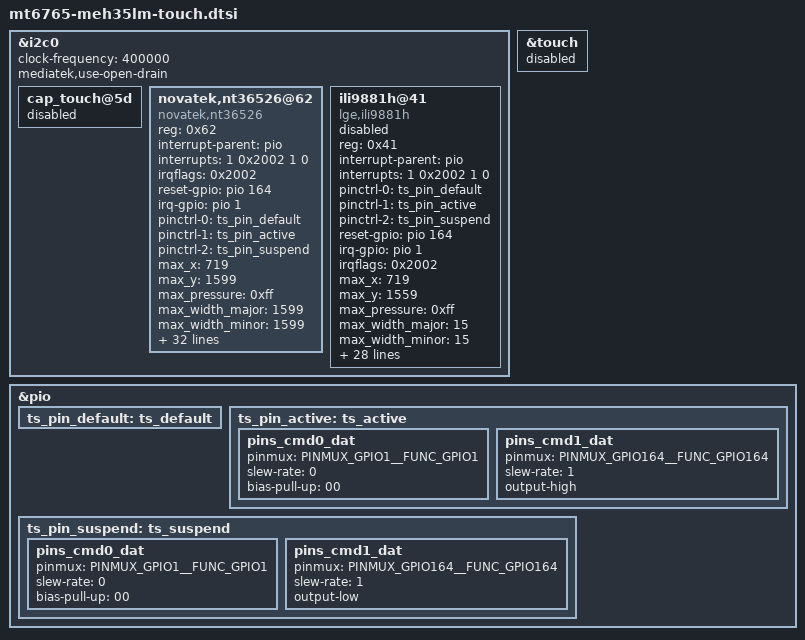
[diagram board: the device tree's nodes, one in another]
/*
 * Copyright (c) 2016, The Linux Foundation. All rights reserved.
 *
 * This program is free software; you can redistribute it and/or modify
 * it under the terms of the GNU General Public License version 2 and
 * only version 2 as published by the Free Software Foundation.
 *
 * This program is distributed in the hope that it will be useful,
 * but WITHOUT ANY WARRANTY; without even the implied warranty of
 * MERCHANTABILITY or FITNESS FOR A PARTICULAR PURPOSE.  See the
 * GNU General Public License for more details.
 */

&i2c0 {
	clock-frequency = <400000>;
	mediatek,use-open-drain;
	cap_touch@5d {
		status = "disabled";
	};
	novatek,nt36526@62 {
		compatible = "novatek,nt36526";
		status = "ok";

		reg = <0x62>;
		interrupt-parent = <&pio>;
		interrupts = <1 0x2002 1 0>;
		irqflags = <0x2002>;

		reset-gpio = <&pio 164 0x00>;
		irq-gpio = <&pio 1 0x2002>;
		//vcl-gpio = <&pio 27 0x00>;	/* 2.8v - VDD */
		//vdd-gpio = <&pio 42 0x00>;    /* 1.8v - IOVCC */

		/* IRQF_ONESHOT		0x00002000 */
		/* IRQF_TRIGGER_FALLING		0x00000002 */
		/* IRQF_NO_SUSPEND		0x00004000 */

		pinctrl-names = "default", "touch_pin_active", "touch_pin_sleep";	/* Touch GPIO pin name setting */
		pinctrl-0 = <&ts_pin_default>;
		pinctrl-1 = <&ts_pin_active>;		/* Touch GPIO pin active setting */
		pinctrl-2 = <&ts_pin_suspend>;		/* Touch GPIO pin suspend setting */

		/*Caps*/
		max_x = <719>;
		max_y = <1599>;
		max_pressure = <0xff>;
		max_width_major = <1599>;
		max_width_minor = <1599>;
		max_orientation = <90>;
		max_id = <10>;
		sw_reset_delay = <200>;
		hw_reset_delay = <200>;

		/* Role */
		use_lpwg = <1>;
		use_lpwg_test = <1>;
		hide_coordinate = <1>;

		/* firmware & panel_spec path */
		use_fw_upgrade = <1>;

		fw_image = "touch/meh35lm/novatek/NT36526_BOE_0659_HDp_LGE_TDDI_PID5505_V19_20200902.bin",
			 "touch/meh35lm/novatek/NT36526_BOE_0659_HDp_LGE_TDDI_PID5506_V02_20200819.bin";
                panel_spec = "touch/meh35lm/novatek/eh35_limit_5505.txt",
                                "touch/meh35lm/novatek/eh35_limit_5506.txt";
                panel_spec_mfts_folder = "touch/meh35lm/novatek/eh35_limit_mfts_5505.txt",
                                "touch/meh35lm/novatek/eh35_limit_mfts_5506.txt";

		/* Performance Test */
		use_perf_test = <1>;
		test_delay = <16>;
		test_pressure = <50>;
		test_width = <100>;
		test_jig_size = <8>;
		click_test_x = <90>;
		click_test_y = <410>;
		v_drag_test_x = <72>;
		v_drag_test_start_y = <971>;
		v_drag_test_end_y = <548>;
		h_drag_test_start_x = <571>;
		h_drag_test_end_x = <148>;
		h_drag_test_y = <1064>;

		/* Novatek customized */

		panel_x_dimention = <69>;    //unit : mm
		panel_y_dimention = <153>;  //unit : mm
	};
	ili9881h@41 {
		compatible = "lge,ili9881h";
		status = "disabled";

		reg = <0x41>;

		/* GPIOs */
		interrupt-parent = <&pio>;
		interrupts = <1 0x2002 1 0>;

		/* IRQF_ONESHOT		0x00002000 */
		/* IRQF_TRIGGER_FALLING		0x00000002 */
		/* IRQF_NO_SUSPEND		0x00004000 */

		pinctrl-names = "default", "touch_pin_active", "touch_pin_sleep";	/* Touch GPIO pin name setting */
		pinctrl-0 = <&ts_pin_default>;
		pinctrl-1 = <&ts_pin_active>;		/* Touch GPIO pin active setting */
		pinctrl-2 = <&ts_pin_suspend>;		/* Touch GPIO pin suspend setting */

		reset-gpio = <&pio 164 0x00>;
		irq-gpio = <&pio 1 0x2002>;
		irqflags = <0x2002>;

		/* Caps */
		max_x = <719>;
		max_y = <1559>;
		max_pressure = <0xff>;
		max_width_major = <15>;
		max_width_minor = <15>;
		max_orientation = <1>;
		max_id = <10>;
		hw_reset_delay = <100>;
		sw_reset_delay = <300>;

		/* Role */
		use_lpwg = <1>;
		use_lpwg_test = <1>;
		hide_coordinate = <0>;

		/* firmware & panel_spec path */
		use_fw_upgrade = <1>;
		use_firmware = <0>;

		fw_image = "touch/mdh30xlm/ilitek/LGE_AUO_ILI9881H_V0_13_AP_1_00_MP_DH30_20200131.bin";
		panel_spec = "touch/mdh30xlm/ilitek/dh30x_limit.txt";
		panel_spec_mfts_folder = "touch/mdh30xlm/ilitek/dh30x_limit_mfts.txt";

		/* Performance Test */
		use_perf_test = <1>;
		test_delay = <8>;
		test_pressure = <50>;
		test_width = <100>;
		test_jig_size = <8>;
		click_test_x = <90>;
		click_test_y = <373>;
		v_drag_test_x = <72>;
		v_drag_test_start_y = <988>;
		v_drag_test_end_y = <571>;
		h_drag_test_start_x = <568>;
		h_drag_test_end_x = <151>;
		h_drag_test_y = <1092>;
	};


};


&touch {
	status = "disabled";
};

/* touch gpio start */
&pio {
	ts_pin_default: ts_default {
	};

	ts_pin_active: ts_active {
		pins_cmd0_dat {
			pinmux = <PINMUX_GPIO1__FUNC_GPIO1>;
			slew-rate = <0>;
			bias-pull-up = <00>;
		};
		pins_cmd1_dat {
			pinmux = <PINMUX_GPIO164__FUNC_GPIO164>;
			slew-rate = <1>;
			output-high;
		};
	};

	ts_pin_suspend: ts_suspend {
		pins_cmd0_dat {
			pinmux = <PINMUX_GPIO1__FUNC_GPIO1>;
			slew-rate = <0>;
			bias-pull-up = <00>;
		};
		pins_cmd1_dat {
			pinmux = <PINMUX_GPIO164__FUNC_GPIO164>;
			slew-rate = <1>;
			output-low;
		};
	};
};
/* touch gpio end */
